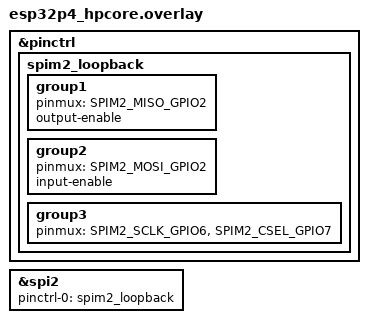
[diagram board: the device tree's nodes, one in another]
/*
 * Copyright (c) 2026 Espressif Systems (Shanghai) Co., Ltd.
 *
 * SPDX-License-Identifier: Apache-2.0
 */

&pinctrl {
	spim2_loopback: spim2_loopback {
		group1 {
			pinmux = <SPIM2_MISO_GPIO2>;
			output-enable;
		};

		group2 {
			pinmux = <SPIM2_MOSI_GPIO2>;
			input-enable;
		};

		group3 {
			pinmux = <SPIM2_SCLK_GPIO6>,
				 <SPIM2_CSEL_GPIO7>;
		};
	};
};

spi_loopback: &spi2 {
	#address-cells = <1>;
	#size-cells = <0>;
	pinctrl-0 = <&spim2_loopback>;
	pinctrl-names = "default";
	status = "okay";
};

#include "../spi-loopback.dtsi"
